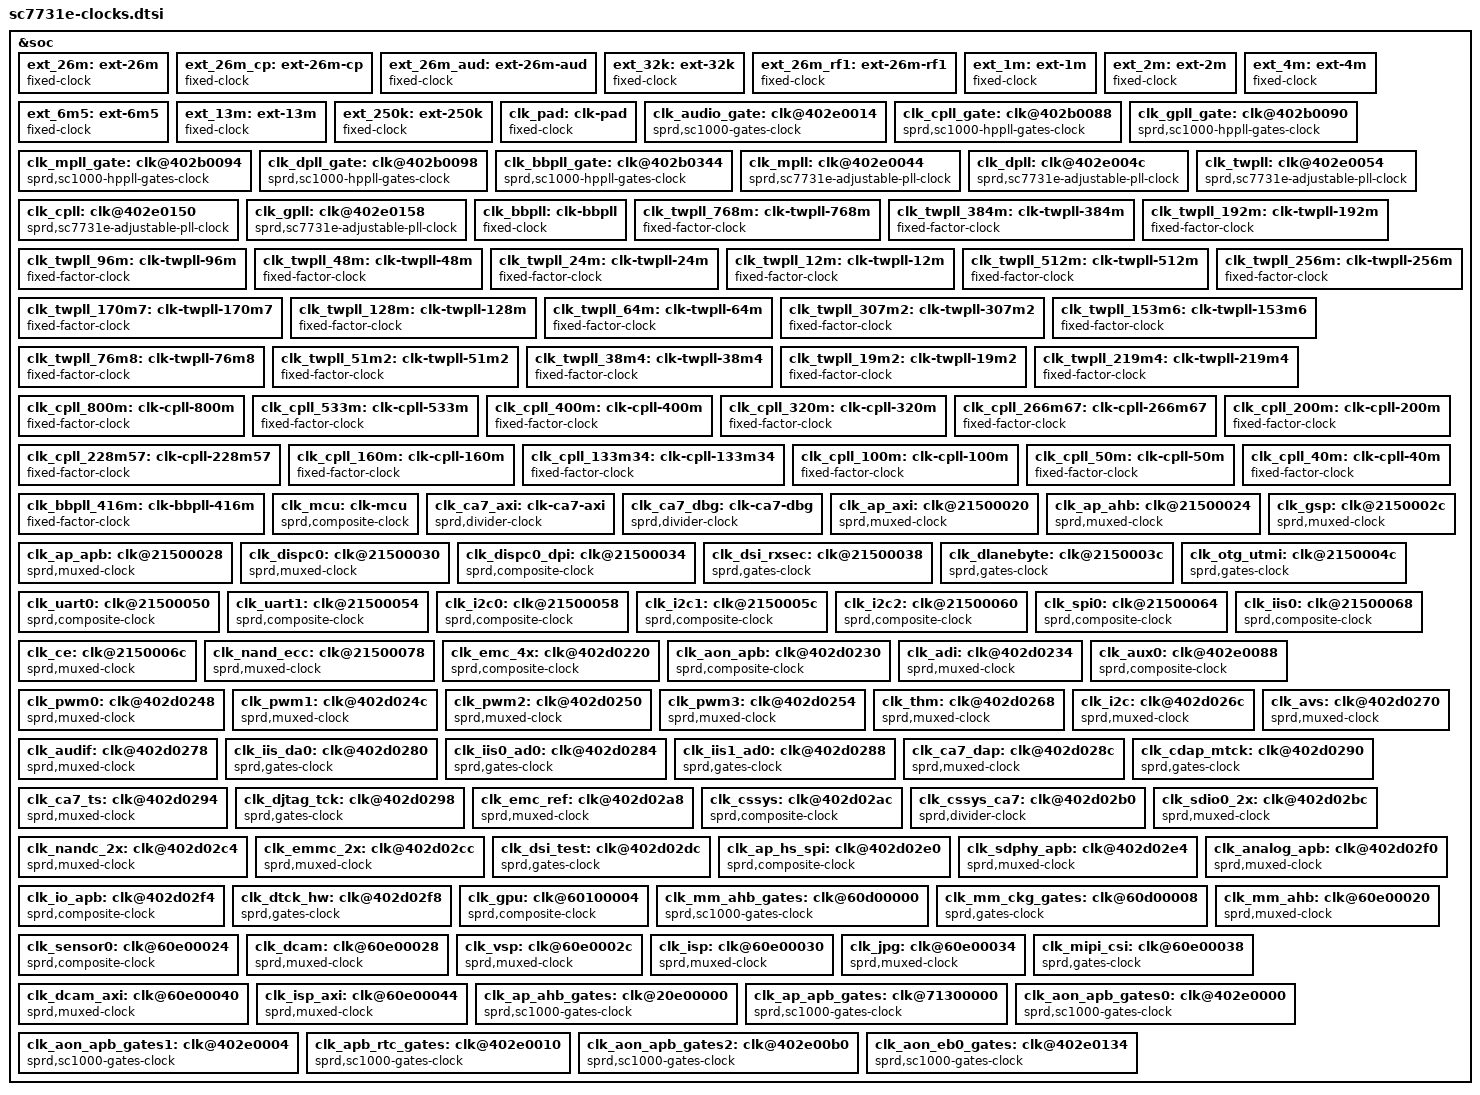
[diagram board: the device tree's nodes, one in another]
/*
 * Spreadtrum Pike2 Series SoC Clock DTS file
 *
 * Copyright (C) 2016, Spreadtrum Communications Inc.
 *
 * This file is licensed under a dual GPLv2 or X11 license.
 */
&soc {
	ext_26m: ext-26m {
		compatible = "fixed-clock";
		#clock-cells = <0>;
		clock-frequency = <26000000>;
		clock-output-names = "ext_26m";
	};

	ext_26m_cp: ext-26m-cp {
		compatible = "fixed-clock";
		#clock-cells = <0>;
		clock-frequency = <26000000>;
		clock-output-names = "ext_26m_cp";
	};

	ext_26m_aud: ext-26m-aud {
		compatible = "fixed-clock";
		#clock-cells = <0>;
		clock-frequency = <26000000>;
		clock-output-names = "ext_26m_aud";
	};

	ext_32k: ext-32k {
		compatible = "fixed-clock";
		#clock-cells = <0>;
		clock-frequency = <32768>;
		clock-output-names = "ext_32k";
	};

	ext_26m_rf1: ext-26m-rf1 {
		compatible = "fixed-clock";
		#clock-cells = <0>;
		clock-frequency = <26000000>;
		clock-output-names = "ext_26m_rf1";
	};

	ext_1m: ext-1m {
		compatible = "fixed-clock";
		#clock-cells = <0>;
		clock-frequency = <1000000>;
		clock-output-names = "ext_1m";
	};

	ext_2m: ext-2m {
		compatible = "fixed-clock";
		#clock-cells = <0>;
		clock-frequency = <2000000>;
		clock-output-names = "ext_2m";
	};

	ext_4m: ext-4m {
		compatible = "fixed-clock";
		#clock-cells = <0>;
		clock-frequency = <4000000>;
		clock-output-names = "ext_4m";
	};

	ext_6m5: ext-6m5 {
		compatible = "fixed-clock";
		#clock-cells = <0>;
		clock-frequency = <6500000>;
		clock-output-names = "ext_6m5";
	};

	ext_13m: ext-13m {
		compatible = "fixed-clock";
		#clock-cells = <0>;
		clock-frequency = <13000000>;
		clock-output-names = "ext_13m";
	};

	ext_250k: ext-250k {
		compatible = "fixed-clock";
		#clock-cells = <0>;
		clock-frequency = <250000>;
		clock-output-names = "ext_250k";
	};

	clk_pad: clk-pad {
		compatible = "fixed-clock";
		#clock-cells = <0>;
		clock-frequency = <64000000>;
		clock-output-names = "clk_pad";
	};

	clk_audio_gate: clk@402e0014 {
		compatible = "sprd,sc1000-gates-clock";
		#clock-cells = <1>;
		sprd,gates-msk = <0x200>;
		reg = <0x402e0014 0x3000>;
		clocks = <&ext_26m>;
		clock-output-names = "clk_audio_gate";
	};

	/* Pll gates */
	clk_cpll_gate: clk@402b0088 {
		compatible = "sprd,sc1000-hppll-gates-clock";
		#clock-cells = <1>;
		sprd,gates-msk = <0x1>;
		reg = <0x402b0088 0x3000>;
		clocks = <&ext_26m>;
		clock-output-names = "clk_cpll_gate";
	};

	clk_gpll_gate: clk@402b0090 {
		compatible = "sprd,sc1000-hppll-gates-clock";
		#clock-cells = <1>;
		sprd,gates-msk = <0x1>;
		reg = <0x402b0090 0x3000>;
		clocks = <&ext_26m>;
		clock-output-names = "clk_gpll_gate";
	};

	clk_mpll_gate: clk@402b0094 {
		compatible = "sprd,sc1000-hppll-gates-clock";
		#clock-cells = <1>;
		sprd,gates-msk = <0x1>;
		reg = <0x402b0094 0x3000>;
		clocks = <&ext_26m>;
		clock-output-names = "clk_mpll_gate";
	};

	clk_dpll_gate: clk@402b0098 {
		compatible = "sprd,sc1000-hppll-gates-clock";
		#clock-cells = <1>;
		sprd,gates-msk = <0x1>;
		reg = <0x402b0098 0x3000>;
		clocks = <&ext_26m>;
		clock-output-names = "clk_dpll_gate";
	};

	clk_bbpll_gate: clk@402b0344 {
		compatible = "sprd,sc1000-hppll-gates-clock";
		#clock-cells = <1>;
		sprd,gates-msk = <0x4>;
		reg = <0x402b0344 0x3000>;
		clocks = <&ext_26m>;
		clock-output-names = "clk_bbpll_gate";
	};

	/* plls */
	clk_mpll: clk@402e0044 {
		compatible = "sprd,sc7731e-adjustable-pll-clock";
		#clock-cells = <0>;
		reg = <0x402e0044 0x4>,
		      <0x402e0048 0x4>;
		clocks = <&clk_mpll_gate 0>;
		clock-output-names = "clk_mpll";
	};

	clk_dpll: clk@402e004c {
		compatible = "sprd,sc7731e-adjustable-pll-clock";
		#clock-cells = <0>;
		reg = <0x402e004c 0x4>,
		      <0x402e0050 0x4>;
		clocks = <&clk_dpll_gate 0>;
		clock-output-names = "clk_dpll";
	};

	clk_twpll: clk@402e0054 {
		compatible = "sprd,sc7731e-adjustable-pll-clock";
		#clock-cells = <0>;
		reg = <0x402e0054 0x4>,
		      <0x402e0058 0x4>;
		clocks = <&ext_26m>;
		clock-output-names = "clk_twpll";
	};

	clk_cpll: clk@402e0150 {
		compatible = "sprd,sc7731e-adjustable-pll-clock";
		#clock-cells = <0>;
		reg = <0x402e0150 0x4>,
		      <0x402e0154 0x4>;
		clocks = <&clk_cpll_gate 0>;
		clock-output-names = "clk_cpll";
	};

	clk_gpll: clk@402e0158 {
		compatible = "sprd,sc7731e-adjustable-pll-clock";
		#clock-cells = <0>;
		reg = <0x402e0158 0x4>,
		      <0x402e015c 0x4>;
		clocks = <&clk_gpll_gate 0>;
		clock-output-names = "clk_gpll";
	};

	clk_bbpll: clk-bbpll {
		compatible = "fixed-clock";
		#clock-cells = <0>;
		clock-frequency = <1248000000>;
		clocks = <&clk_bbpll_gate 2>;
		clock-output-names = "clk_bbpll";
	};

	/* TWPLL divider clocks */
	clk_twpll_768m: clk-twpll-768m {
		compatible = "fixed-factor-clock";
		#clock-cells = <0>;
		clock-mult = <1>;
		clock-div  = <2>;
		clocks = <&clk_twpll>;
		clock-output-names = "clk_twpll_768m";
	};

	clk_twpll_384m: clk-twpll-384m {
		compatible = "fixed-factor-clock";
		#clock-cells = <0>;
		clock-mult = <1>;
		clock-div  = <4>;
		clocks = <&clk_twpll>;
		clock-output-names = "clk_twpll_384m";
	};

	clk_twpll_192m: clk-twpll-192m {
		compatible = "fixed-factor-clock";
		#clock-cells = <0>;
		clock-mult = <1>;
		clock-div  = <8>;
		clocks = <&clk_twpll>;
		clock-output-names = "clk_twpll_192m";
	};

	clk_twpll_96m: clk-twpll-96m {
		compatible = "fixed-factor-clock";
		#clock-cells = <0>;
		clock-mult = <1>;
		clock-div  = <16>;
		clocks = <&clk_twpll>;
		clock-output-names = "clk_twpll_96m";
	};

	clk_twpll_48m: clk-twpll-48m {
		compatible = "fixed-factor-clock";
		#clock-cells = <0>;
		clock-mult = <1>;
		clock-div  = <32>;
		clocks = <&clk_twpll>;
		clock-output-names = "clk_twpll_48m";
	};

	clk_twpll_24m: clk-twpll-24m {
		compatible = "fixed-factor-clock";
		#clock-cells = <0>;
		clock-mult = <1>;
		clock-div  = <64>;
		clocks = <&clk_twpll>;
		clock-output-names = "clk_twpll_24m";
	};

	clk_twpll_12m: clk-twpll-12m {
		compatible = "fixed-factor-clock";
		#clock-cells = <0>;
		clock-mult = <1>;
		clock-div  = <128>;
		clocks = <&clk_twpll>;
		clock-output-names = "clk_twpll_12m";
	};

	clk_twpll_512m: clk-twpll-512m {
		compatible = "fixed-factor-clock";
		#clock-cells = <0>;
		clock-mult = <1>;
		clock-div  = <3>;
		clocks = <&clk_twpll>;
		clock-output-names = "clk_twpll_512m";
	};

	clk_twpll_256m: clk-twpll-256m {
		compatible = "fixed-factor-clock";
		#clock-cells = <0>;
		clock-mult = <1>;
		clock-div  = <6>;
		clocks = <&clk_twpll>;
		clock-output-names = "clk_twpll_256m";
	};

	clk_twpll_170m7: clk-twpll-170m7 {
		compatible = "fixed-factor-clock";
		#clock-cells = <0>;
		clock-mult = <1>;
		clock-div  = <9>;
		clocks = <&clk_twpll>;
		clock-output-names = "clk_twpll_170m7";
	};

	clk_twpll_128m: clk-twpll-128m {
		compatible = "fixed-factor-clock";
		#clock-cells = <0>;
		clock-mult = <1>;
		clock-div  = <12>;
		clocks = <&clk_twpll>;
		clock-output-names = "clk_twpll_128m";
	};

	clk_twpll_64m: clk-twpll-64m {
		compatible = "fixed-factor-clock";
		#clock-cells = <0>;
		clock-mult = <1>;
		clock-div  = <24>;
		clocks = <&clk_twpll>;
		clock-output-names = "clk_twpll_64m";
	};

	clk_twpll_307m2: clk-twpll-307m2 {
		compatible = "fixed-factor-clock";
		#clock-cells = <0>;
		clock-mult = <1>;
		clock-div  = <5>;
		clocks = <&clk_twpll>;
		clock-output-names = "clk_twpll_307m2";
	};

	clk_twpll_153m6: clk-twpll-153m6 {
		compatible = "fixed-factor-clock";
		#clock-cells = <0>;
		clock-mult = <1>;
		clock-div  = <10>;
		clocks = <&clk_twpll>;
		clock-output-names = "clk_twpll_153m6";
	};

	clk_twpll_76m8: clk-twpll-76m8 {
		compatible = "fixed-factor-clock";
		#clock-cells = <0>;
		clock-mult = <1>;
		clock-div  = <20>;
		clocks = <&clk_twpll>;
		clock-output-names = "clk_twpll_76m8";
	};

	clk_twpll_51m2: clk-twpll-51m2 {
		compatible = "fixed-factor-clock";
		#clock-cells = <0>;
		clock-mult = <1>;
		clock-div  = <30>;
		clocks = <&clk_twpll>;
		clock-output-names = "clk_twpll_51m2";
	};

	clk_twpll_38m4: clk-twpll-38m4 {
		compatible = "fixed-factor-clock";
		#clock-cells = <0>;
		clock-mult = <1>;
		clock-div  = <40>;
		clocks = <&clk_twpll>;
		clock-output-names = "clk_twpll_38m4";
	};

	clk_twpll_19m2: clk-twpll-19m2 {
		compatible = "fixed-factor-clock";
		#clock-cells = <0>;
		clock-mult = <1>;
		clock-div  = <80>;
		clocks = <&clk_twpll>;
		clock-output-names = "clk_twpll_19m2";
	};

	clk_twpll_219m4: clk-twpll-219m4 {
		compatible = "fixed-factor-clock";
		#clock-cells = <0>;
		clock-mult = <1>;
		clock-div  = <7>;
		clocks = <&clk_twpll>;
		clock-output-names = "clk_twpll_219m4";
	};

	/* cpll divider clock */
	clk_cpll_800m: clk-cpll-800m {
		compatible = "fixed-factor-clock";
		#clock-cells = <0>;
		clock-mult = <1>;
		clock-div  = <2>;
		clocks = <&clk_cpll>;
		clock-output-names = "clk_cpll_800m";
	};

	clk_cpll_533m: clk-cpll-533m {
		compatible = "fixed-factor-clock";
		#clock-cells = <0>;
		clock-mult = <1>;
		clock-div  = <3>;
		clocks = <&clk_cpll>;
		clock-output-names = "clk_cpll_533m";
	};

	clk_cpll_400m: clk-cpll-400m {
		compatible = "fixed-factor-clock";
		#clock-cells = <0>;
		clock-mult = <1>;
		clock-div  = <4>;
		clocks = <&clk_cpll>;
		clock-output-names = "clk_cpll_400m";
	};

	clk_cpll_320m: clk-cpll-320m {
		compatible = "fixed-factor-clock";
		#clock-cells = <0>;
		clock-mult = <1>;
		clock-div  = <5>;
		clocks = <&clk_cpll>;
		clock-output-names = "clk_cpll_320m";
	};

	clk_cpll_266m67: clk-cpll-266m67 {
		compatible = "fixed-factor-clock";
		#clock-cells = <0>;
		clock-mult = <1>;
		clock-div  = <6>;
		clocks = <&clk_cpll>;
		clock-output-names = "clk_cpll_266m67";
	};

	clk_cpll_228m57: clk-cpll-228m57 {
		compatible = "fixed-factor-clock";
		#clock-cells = <0>;
		clock-mult = <1>;
		clock-div  = <7>;
		clocks = <&clk_cpll>;
		clock-output-names = "clk_cpll_228m57";
	};

	clk_cpll_200m: clk-cpll-200m {
		compatible = "fixed-factor-clock";
		#clock-cells = <0>;
		clock-mult = <1>;
		clock-div  = <8>;
		clocks = <&clk_cpll>;
		clock-output-names = "clk_cpll_200m";
	};

	clk_cpll_160m: clk-cpll-160m {
		compatible = "fixed-factor-clock";
		#clock-cells = <0>;
		clock-mult = <1>;
		clock-div  = <10>;
		clocks = <&clk_cpll>;
		clock-output-names = "clk_cpll_160m";
	};

	clk_cpll_133m34: clk-cpll-133m34 {
		compatible = "fixed-factor-clock";
		#clock-cells = <0>;
		clock-mult = <1>;
		clock-div  = <12>;
		clocks = <&clk_cpll>;
		clock-output-names = "clk_cpll_133m34";
	};

	clk_cpll_100m: clk-cpll-100m {
		compatible = "fixed-factor-clock";
		#clock-cells = <0>;
		clock-mult = <1>;
		clock-div  = <16>;
		clocks = <&clk_cpll>;
		clock-output-names = "clk_cpll_100m";
	};

	clk_cpll_50m: clk-cpll-50m {
		compatible = "fixed-factor-clock";
		#clock-cells = <0>;
		clock-mult = <1>;
		clock-div  = <32>;
		clocks = <&clk_cpll>;
		clock-output-names = "clk_cpll_50m";
	};

	clk_cpll_40m: clk-cpll-40m {
		compatible = "fixed-factor-clock";
		#clock-cells = <0>;
		clock-mult = <1>;
		clock-div  = <40>;
		clocks = <&clk_cpll>;
		clock-output-names = "clk_cpll_40m";
	};

	clk_bbpll_416m: clk-bbpll-416m {
		compatible = "fixed-factor-clock";
		#clock-cells = <0>;
		clock-mult = <1>;
		clock-div  = <3>;
		clocks = <&clk_bbpll>;
		clock-output-names = "clk_bbpll_416m";
	};

	/* ap clocks */
	clk_mcu: clk-mcu {
		compatible = "sprd,composite-clock";
		#clock-cells = <0>;
		reg = <0x20e00054 0x4>,
		      <0x20e00038 0x4>;
		sprd,mux-msk = <0x7>;
		sprd,div-msk = <0x70>;
		clocks = <&ext_26m>, <&clk_twpll_512m>,
			 <&clk_twpll_768m>, <&clk_dpll>,
			 <&clk_cpll>, <&clk_twpll>, <&clk_mpll>;
		clock-output-names = "clk_mcu";
	};

	clk_ca7_axi: clk-ca7-axi {
		compatible = "sprd,divider-clock";
		#clock-cells = <0>;
		sprd,div-msk = <0x700>;
		clocks = <&clk_mcu>;
		clock-output-names = "clk_ca7_axi";
	};

	clk_ca7_dbg: clk-ca7-dbg {
		compatible = "sprd,divider-clock";
		#clock-cells = <0>;
		sprd,div-msk = <0x70000>;
		clocks = <&clk_mcu>;
		clock-output-names = "clk_ca7_dbg";
	};

	clk_ap_axi: clk@21500020 {
		compatible = "sprd,muxed-clock";
		#clock-cells = <0>;
		reg = <0x21500020 0x4>;
		sprd,mux-msk = <0x7>;
		clocks = <&ext_26m>, <&clk_twpll_76m8>,
			 <&clk_twpll_128m>, <&clk_twpll_256m>,
			 <&clk_cpll_266m67>;
		clock-output-names = "clk_ap_axi";
	};

	clk_ap_ahb: clk@21500024 {
		compatible = "sprd,muxed-clock";
		#clock-cells = <0>;
		reg = <0x21500024 0x4>;
		sprd,mux-msk = <0x7>;
		clocks = <&ext_26m>, <&clk_twpll_76m8>,
			 <&clk_twpll_128m>, <&clk_twpll_192m>,
			 <&clk_cpll_200m>;
		clock-output-names = "clk_ap_ahb";
	};

	clk_ap_apb: clk@21500028 {
		compatible = "sprd,muxed-clock";
		#clock-cells = <0>;
		reg = <0x21500028 0x4>;
		sprd,mux-msk = <0x7>;
		clocks = <&ext_26m>, <&clk_twpll_64m>,
			 <&clk_twpll_96m>, <&clk_cpll_100m>,
			 <&clk_twpll_128m>;
		clock-output-names = "clk_ap_apb";
	};

	clk_gsp: clk@2150002c {
		compatible = "sprd,muxed-clock";
		#clock-cells = <0>;
		reg = <0x2150002c 0x4>;
		sprd,mux-msk = <0x7>;
		clocks = <&clk_twpll_153m6>, <&clk_twpll_256m>,
			 <&clk_twpll_307m2>, <&clk_cpll_320m>,
			 <&clk_twpll_384m>;
		clock-output-names = "clk_gsp";
	};

	clk_dispc0: clk@21500030 {
		compatible = "sprd,muxed-clock";
		#clock-cells = <0>;
		reg = <0x21500030 0x4>;
		sprd,mux-msk = <0x7>;
		clocks = <&clk_twpll_128m>, <&clk_twpll_153m6>,
			 <&clk_twpll_192m>, <&clk_twpll_256m>,
			 <&clk_cpll_320m>, <&clk_twpll_384m>;
		clock-output-names = "clk_dispc0";
	};

	clk_dispc0_dpi:clk@21500034 {
		compatible = "sprd,composite-clock";
		#clock-cells = <0>;
		reg = <0x21500034 0x4>;
		sprd,mux-msk = <0x7>;
		sprd,div-msk = <0xf00>;
		clocks = <&clk_twpll_96m>, <&clk_cpll_100m>,
			 <&clk_twpll_128m>, <&clk_twpll_153m6>,
			 <&clk_twpll_192m>;
		clock-output-names = "clk_dispc0_dpi";
	};

	clk_dsi_rxsec: clk@21500038 {
		compatible = "sprd,gates-clock";
		#clock-cells = <1>;
		reg = <0x21500038 0x4>;
		sprd,gates-msk = <0x10000>;
		clocks = <&clk_ap_ahb>;
		clock-output-names = "clk_dsi_rxsec";
	};

	clk_dlanebyte: clk@2150003c {
		compatible = "sprd,gates-clock";
		#clock-cells = <1>;
		reg = <0x2150003c 0x4>;
		sprd,gates-msk = <0x10000>;
		clocks = <&clk_ap_ahb>;
		clock-output-names = "clk_dlanebyte";
	};

	clk_otg_utmi: clk@2150004c {
		compatible = "sprd,gates-clock";
		#clock-cells = <1>;
		reg = <0x2150004c 0x4>;
		sprd,gates-msk = <0x10000>;
		clocks = <&clk_ap_ahb>;
		clock-output-names = "clk_otg_utmi";
	};

	clk_uart0:clk@21500050 {
		compatible = "sprd,composite-clock";
		#clock-cells = <0>;
		reg = <0x21500050 0x4>;
		sprd,mux-msk = <0x3>;
		sprd,div-msk = <0x700>;
		clocks = <&ext_26m>, <&clk_twpll_48m>,
			 <&clk_twpll_51m2>, <&clk_twpll_96m>;
		clock-output-names = "clk_uart0";
	};

	clk_uart1:clk@21500054 {
		compatible = "sprd,composite-clock";
		#clock-cells = <0>;
		reg = <0x21500054 0x4>;
		sprd,mux-msk = <0x3>;
		sprd,div-msk = <0x700>;
		clocks = <&ext_26m>, <&clk_twpll_48m>,
			 <&clk_twpll_51m2>, <&clk_twpll_96m>;
		clock-output-names = "clk_uart1";
	};

	clk_i2c0:clk@21500058 {
		compatible = "sprd,composite-clock";
		#clock-cells = <0>;
		reg = <0x21500058 0x4>;
		sprd,mux-msk = <0x3>;
		sprd,div-msk = <0x700>;
		clocks = <&ext_26m>, <&clk_twpll_48m>,
			 <&clk_twpll_51m2>, <&clk_twpll_153m6>;
		clock-output-names = "clk_i2c0";
	};

	clk_i2c1:clk@2150005c {
		compatible = "sprd,composite-clock";
		#clock-cells = <0>;
		reg = <0x2150005c 0x4>;
		sprd,mux-msk = <0x3>;
		sprd,div-msk = <0x700>;
		clocks = <&ext_26m>, <&clk_twpll_48m>,
			 <&clk_twpll_51m2>, <&clk_twpll_153m6>;
		clock-output-names = "clk_i2c1";
	};

	clk_i2c2:clk@21500060 {
		compatible = "sprd,composite-clock";
		#clock-cells = <0>;
		reg = <0x21500060 0x4>;
		sprd,mux-msk = <0x3>;
		sprd,div-msk = <0x700>;
		clocks = <&ext_26m>, <&clk_twpll_48m>,
			 <&clk_twpll_51m2>, <&clk_twpll_153m6>;
		clock-output-names = "clk_i2c2";
	};

	clk_spi0:clk@21500064 {
		compatible = "sprd,composite-clock";
		#clock-cells = <0>;
		reg = <0x21500064 0x4>;
		sprd,mux-msk = <0x7>;
		sprd,div-msk = <0x700>;
		clocks = <&ext_26m>, <&clk_cpll_100m>,
			 <&clk_twpll_128m>, <&clk_twpll_153m6>,
			 <&clk_twpll_192m>;
		clock-output-names = "clk_spi0";
	};

	clk_iis0:clk@21500068 {
		compatible = "sprd,composite-clock";
		#clock-cells = <0>;
		reg = <0x21500068 0x4>;
		sprd,mux-msk = <0x3>;
		sprd,div-msk = <0x700>;
		clocks = <&ext_26m>, <&clk_twpll_128m>, <&clk_twpll_153m6>;
		clock-output-names = "clk_iis0";
	};

	clk_ce: clk@2150006c {
		compatible = "sprd,muxed-clock";
		#clock-cells = <0>;
		reg = <0x2150006c 0x4>;
		sprd,mux-msk = <0x7>;
		clocks = <&ext_26m>, <&clk_twpll_96m>,
			 <&clk_cpll_100m>, <&clk_twpll_192m>,
			 <&clk_twpll_256m>;
		clock-output-names = "clk_ce";
	};

	clk_nand_ecc: clk@21500078 {
		compatible = "sprd,muxed-clock";
		#clock-cells = <0>;
		reg = <0x21500078 0x4>;
		sprd,mux-msk = <0x3>;
		clocks = <&ext_26m>, <&clk_cpll_200m>,
			 <&clk_twpll_256m>, <&clk_twpll_307m2>;
		clock-output-names = "clk_nand_ecc";
	};

	/* aon clocks */
	clk_emc_4x:clk@402d0220 {
		compatible = "sprd,composite-clock";
		#clock-cells = <0>;
		reg = <0x402d0220 0x4>;
		sprd,mux-msk = <0x7>;
		sprd,div-msk = <0x300>;
		clocks = <&ext_26m>, <&clk_twpll_384m>,
			 <&clk_twpll_512m>, <&clk_twpll_768m>,
			 <&clk_cpll_800m>, <&clk_dpll>;
		clock-output-names = "clk_emc_4x";
	};

	clk_aon_apb:clk@402d0230 {
		compatible = "sprd,composite-clock";
		#clock-cells = <0>;
		reg = <0x402d0230 0x4>;
		sprd,mux-msk = <0x3>;
		sprd,div-msk = <0x300>;
		clocks = <&ext_26m>, <&clk_cpll_100m>,
			 <&clk_twpll_128m>;
		clock-output-names = "clk_aon_apb";
	};

	clk_adi: clk@402d0234 {
		compatible = "sprd,muxed-clock";
		#clock-cells = <0>;
		reg = <0x402d0234 0x4>;
		sprd,mux-msk = <0x3>;
		clocks = <&ext_26m>, <&clk_cpll_50m>,
			 <&clk_twpll_51m2>;
		clock-output-names = "clk_adi";
	};

	clk_aux0: clk@402e0088 {
		compatible = "sprd,composite-clock";
		#clock-cells = <0>;
		reg = <0x402e0088 0x4>;
		sprd,mux-msk = <0x3>;
		sprd,div-msk = <0xf0000>;
		clocks = <&ext_32k>, <&ext_26m_cp>,
			 <&ext_26m>;
		clock-output-names = "clk_aux0";
	};

	clk_pwm0: clk@402d0248 {
		compatible = "sprd,muxed-clock";
		#clock-cells = <0>;
		reg = <0x402d0248 0x4>;
		sprd,mux-msk = <0x7>;
		clocks = <&ext_32k>, <&ext_26m_cp>,
			 <&ext_26m>, <&clk_cpll_40m>,
			 <&clk_twpll_48m>;
		clock-output-names = "clk_pwm0";
	};

	clk_pwm1: clk@402d024c {
		compatible = "sprd,muxed-clock";
		#clock-cells = <0>;
		reg = <0x402d024c 0x4>;
		sprd,mux-msk = <0x7>;
		clocks = <&ext_32k>, <&ext_26m_cp>,
			 <&ext_26m>, <&clk_cpll_40m>,
			 <&clk_twpll_48m>;
		clock-output-names = "clk_pwm1";
	};

	clk_pwm2: clk@402d0250 {
		compatible = "sprd,muxed-clock";
		#clock-cells = <0>;
		reg = <0x402d0250 0x4>;
		sprd,mux-msk = <0x7>;
		clocks = <&ext_32k>, <&ext_26m_cp>,
			 <&ext_26m>, <&clk_cpll_40m>,
			 <&clk_twpll_48m>;
		clock-output-names = "clk_pwm2";
	};

	clk_pwm3: clk@402d0254 {
		compatible = "sprd,muxed-clock";
		#clock-cells = <0>;
		reg = <0x402d0254 0x4>;
		sprd,mux-msk = <0x7>;
		clocks = <&ext_32k>, <&ext_26m_cp>,
			 <&ext_26m>, <&clk_cpll_40m>,
			 <&clk_twpll_48m>;
		clock-output-names = "clk_pwm3";
	};

	clk_thm: clk@402d0268 {
		compatible = "sprd,muxed-clock";
		#clock-cells = <0>;
		reg = <0x402d0268 0x4>;
		sprd,mux-msk = <0x1>;
		clocks = <&ext_32k>, <&ext_250k>;
		clock-output-names = "clk_thm";
	};

	clk_i2c: clk@402d026c {
		compatible = "sprd,muxed-clock";
		#clock-cells = <0>;
		reg = <0x402d026c 0x4>;
		sprd,mux-msk = <0x7>;
		clocks = <&ext_26m>, <&clk_twpll_48m>,
			 <&clk_twpll_51m2>, <&clk_cpll_133m34>,
			 <&clk_twpll_153m6>;
		clock-output-names = "clk_i2c";
	};

	clk_avs: clk@402d0270 {
		compatible = "sprd,muxed-clock";
		#clock-cells = <0>;
		reg = <0x402d0270 0x4>;
		sprd,mux-msk = <0x7>;
		clocks = <&ext_26m>, <&clk_twpll_48m>,
			 <&clk_cpll_50m>, <&clk_twpll_51m2>,
			 <&clk_twpll_96m>;
		clock-output-names = "clk_avs";
	};

	clk_audif: clk@402d0278 {
		compatible = "sprd,muxed-clock";
		#clock-cells = <0>;
		reg = <0x402d0278 0x4>;
		sprd,mux-msk = <0x3>;
		clocks = <&ext_26m_aud>, <&clk_twpll_38m4>,
			 <&clk_cpll_50m>, <&clk_twpll_51m2>;
		clock-output-names = "clk_audif";
	};

	clk_iis_da0: clk@402d0280 {
		compatible = "sprd,gates-clock";
		#clock-cells = <1>;
		reg = <0x402d0280 0x4>;
		sprd,gates-msk = <0x10000>;
		clocks = <&clk_aon_apb>;
		clock-output-names = "clk_iis_da0";
	};

	clk_iis0_ad0: clk@402d0284 {
		compatible = "sprd,gates-clock";
		#clock-cells = <1>;
		reg = <0x402d0284 0x4>;
		sprd,gates-msk = <0x10000>;
		clocks = <&clk_aon_apb>;
		clock-output-names = "clk_iis0_ad0";
	};

	clk_iis1_ad0: clk@402d0288 {
		compatible = "sprd,gates-clock";
		#clock-cells = <1>;
		reg = <0x402d0288 0x4>;
		sprd,gates-msk = <0x10000>;
		clocks = <&clk_aon_apb>;
		clock-output-names = "clk_iis1_ad0";
	};

	clk_ca7_dap: clk@402d028c {
		compatible = "sprd,muxed-clock";
		#clock-cells = <0>;
		reg = <0x402d028c 0x4>;
		sprd,mux-msk = <0x3>;
		clocks = <&ext_26m_aud>, <&clk_twpll_76m8>,
			 <&clk_cpll_100m>, <&clk_twpll_153m6>;
		clock-output-names = "clk_ca7_dap";
	};

	clk_cdap_mtck: clk@402d0290 {
		compatible = "sprd,gates-clock";
		#clock-cells = <1>;
		reg = <0x402d0290 0x4>;
		sprd,gates-msk = <0x10000>;
		clocks = <&clk_aon_apb>;
		clock-output-names = "clk_cdap_mtck";
	};

	clk_ca7_ts: clk@402d0294 {
		compatible = "sprd,muxed-clock";
		#clock-cells = <0>;
		reg = <0x402d0294 0x4>;
		sprd,mux-msk = <0x7>;
		clocks = <&ext_32k>, <&ext_26m>,
			 <&clk_twpll_128m>, <&clk_cpll_133m34>,
			 <&clk_twpll_153m6>;
		clock-output-names = "clk_ca7_ts";
	};

	clk_djtag_tck: clk@402d0298 {
		compatible = "sprd,gates-clock";
		#clock-cells = <1>;
		reg = <0x402d0298 0x4>;
		sprd,gates-msk = <0x10000>;
		clocks = <&clk_aon_apb>;
		clock-output-names = "clk_djtag_tck";
	};

	clk_emc_ref: clk@402d02a8 {
		compatible = "sprd,muxed-clock";
		#clock-cells = <0>;
		reg = <0x402d02a8 0x4>;
		sprd,mux-msk = <0x3>;
		clocks = <&ext_6m5>, <&ext_13m>, <&ext_26m>;
		clock-output-names = "clk_emc_ref";
	};

	clk_cssys:clk@402d02ac {
		compatible = "sprd,composite-clock";
		#clock-cells = <0>;
		reg = <0x402d02ac 0x4>;
		sprd,mux-msk = <0x7>;
		sprd,div-msk = <0x300>;
		clocks = <&ext_26m>, <&clk_twpll_96m>,
			 <&clk_twpll_128m>, <&clk_twpll_153m6>,
			 <&clk_cpll_266m67>, <&clk_twpll_384m>,
			 <&clk_twpll_512m>;
		clock-output-names = "clk_cssys";
	};

	clk_cssys_ca7: clk@402d02b0 {
		compatible = "sprd,divider-clock";
		#clock-cells = <0>;
		reg = <0x402d02b0 0x4>;
		sprd,div-msk = <0x100>;
		clocks = <&clk_cssys>;
		clock-output-names = "clk_cssys_ca7";
	};

	clk_sdio0_2x: clk@402d02bc {
		compatible = "sprd,muxed-clock";
		#clock-cells = <0>;
		reg = <0x402d02bc 0x4>;
		sprd,mux-msk = <0x7>;
		clocks = <&ext_1m>, <&ext_26m>, <&clk_twpll_307m2>,
			 <&clk_twpll_384m>, <&clk_cpll_400m>,
			 <&clk_bbpll_416m>;
		clock-output-names = "clk_sdio0_2x";
	};

	clk_nandc_2x: clk@402d02c4 {
		compatible = "sprd,muxed-clock";
		#clock-cells = <0>;
		reg = <0x402d02c4 0x4>;
		sprd,mux-msk = <0x7>;
		clocks = <&ext_1m>, <&ext_26m>, <&clk_twpll_153m6>,
			 <&clk_twpll_170m7>, <&clk_cpll_200m>,
			 <&clk_twpll_219m4>, <&clk_cpll_228m57>,
			 <&clk_cpll_266m67>;
		clock-output-names = "clk_nandc_2x";
	};

	clk_emmc_2x: clk@402d02cc {
		compatible = "sprd,muxed-clock";
		#clock-cells = <0>;
		reg = <0x402d02cc 0x4>;
		sprd,mux-msk = <0x7>;
		clocks = <&ext_1m>, <&ext_26m>, <&clk_twpll_307m2>,
			 <&clk_twpll_384m>, <&clk_cpll_400m>,
			 <&clk_bbpll_416m>;
		clock-output-names = "clk_emmc_2x";
	};

	clk_dsi_test: clk@402d02dc {
		compatible = "sprd,gates-clock";
		#clock-cells = <1>;
		reg = <0x402d02dc 0x4>;
		sprd,gates-msk = <0x10000>;
		clocks = <&clk_aon_apb>;
		clock-output-names = "clk_dsi_test";
	};

	clk_ap_hs_spi:clk@402d02e0 {
		compatible = "sprd,composite-clock";
		#clock-cells = <0>;
		reg = <0x402d02e0 0x4>;
		sprd,mux-msk = <0x7>;
		sprd,div-msk = <0x700>;
		clocks = <&ext_26m>, <&clk_twpll_128m>,
			 <&clk_cpll_133m34>, <&clk_twpll_153m6>,
			 <&clk_twpll_192m>;
		clock-output-names = "clk_ap_hs_spi";
	};

	clk_sdphy_apb: clk@402d02e4 {
		compatible = "sprd,muxed-clock";
		#clock-cells = <0>;
		reg = <0x402d02e4 0x4>;
		sprd,mux-msk = <0x3>;
		clocks = <&ext_26m>, <&clk_cpll_40m>,
			 <&clk_twpll_48m>;
		clock-output-names = "clk_sdphy_apb";
	};

	clk_analog_apb: clk@402d02f0 {
		compatible = "sprd,muxed-clock";
		#clock-cells = <0>;
		reg = <0x402d02f0 0x4>;
		sprd,mux-msk = <0x7>;
		clocks = <&ext_26m>, <&clk_cpll_40m>,
			 <&clk_twpll_48m>;
		clock-output-names = "clk_analog_apb";
	};

	clk_io_apb: clk@402d02f4 {
		compatible = "sprd,composite-clock";
		#clock-cells = <0>;
		reg = <0x402d02f4 0x4>;
		sprd,mux-msk = <0x3>;
		sprd,div-msk = <0x300>;
		clocks = <&ext_26m>, <&clk_cpll_40m>,
			 <&clk_twpll_48m>;
		clock-output-names = "clk_io_apb";
	};

	clk_dtck_hw: clk@402d02f8 {
		compatible = "sprd,gates-clock";
		#clock-cells = <1>;
		reg = <0x402d02f8 0x4>;
		sprd,gates-msk = <0x10000>;
		clocks = <&clk_aon_apb>;
		clock-output-names = "clk_dtck_hw";
	};

	/* gpu clocks */
	clk_gpu:clk@60100004 {
		compatible = "sprd,composite-clock";
		#clock-cells = <0>;
		reg = <0x60100004 0x4>;
		sprd,mux-msk = <0x7>;
		sprd,div-msk = <0x30>;
		clocks = <&clk_twpll_153m6>, <&clk_twpll_192m>,
			 <&clk_twpll_256m>, <&clk_twpll_307m2>,
			 <&clk_twpll_384m>, <&clk_twpll_512m>,
			 <&clk_gpll>;
		clock-output-names = "clk_gpu";
	};

	/* mm domain clocks */
	clk_mm_ahb_gates: clk@60d00000 {
		compatible = "sprd,sc1000-gates-clock";
		#clock-cells = <1>;
		reg = <0x60d00000 0x3000>;
		sprd,gates-msk = <0x7f>;
		clocks = <&clk_mm_ahb>;
		clock-output-names = "dcam_eb", "isp_eb", "vsp_eb",
				     "csi_eb", "jpg_eb", "mm_ckg_eb",
				     "vsp_mq_ahb_eb";
	};

	clk_mm_ckg_gates: clk@60d00008 {
		compatible = "sprd,gates-clock";
		#clock-cells = <1>;
		reg = <0x60d00008 0x4>;
		sprd,gates-msk = <0x1f>;
		clocks = <&clk_mm_ahb>;
		clock-output-names = "mcphy_cfg_eb", "msensor0_en",
				     "misp_axi_en", "mdcam_axi_en",
				     "mmipi_csi_en";
	};

	clk_mm_ahb: clk@60e00020 {
		compatible = "sprd,muxed-clock";
		#clock-cells = <0>;
		reg = <0x60e00020 0x4>;
		sprd,mux-msk = <0x7>;
		clocks = <&ext_26m>, <&clk_twpll_96m>,
			 <&clk_twpll_128m>, <&clk_twpll_153m6>,
			 <&clk_cpll_160m>;
		clock-output-names = "clk_mm_ahb";
	};

	clk_sensor0:clk@60e00024 {
		compatible = "sprd,composite-clock";
		#clock-cells = <0>;
		reg = <0x60e00024 0x4>;
		sprd,mux-msk = <0x3>;
		sprd,div-msk = <0x700>;
		clocks = <&ext_26m>, <&clk_twpll_48m>,
			 <&clk_twpll_76m8>, <&clk_twpll_96m>;
		clock-output-names = "clk_sensor0";
	};

	clk_dcam: clk@60e00028 {
		compatible = "sprd,muxed-clock";
		#clock-cells = <0>;
		reg = <0x60e00028 0x4>;
		sprd,mux-msk = <0x3>;
		clocks = <&clk_twpll_128m>, <&clk_twpll_256m>,
			 <&clk_twpll_307m2>, <&clk_cpll_320m>;
		clock-output-names = "clk_dcam";
	};

	clk_vsp: clk@60e0002c {
		compatible = "sprd,muxed-clock";
		#clock-cells = <0>;
		reg = <0x60e0002c 0x4>;
		sprd,mux-msk = <0x3>;
		clocks = <&clk_twpll_128m>, <&clk_twpll_256m>,
			 <&clk_twpll_307m2>, <&clk_cpll_320m>;
		clock-output-names = "clk_vsp";
	};

	clk_isp: clk@60e00030 {
		compatible = "sprd,muxed-clock";
		#clock-cells = <0>;
		reg = <0x60e00030 0x4>;
		sprd,mux-msk = <0x3>;
		clocks = <&clk_twpll_128m>, <&clk_twpll_256m>,
			 <&clk_twpll_307m2>, <&clk_cpll_320m>;
		clock-output-names = "clk_isp";
	};

	clk_jpg: clk@60e00034 {
		compatible = "sprd,muxed-clock";
		#clock-cells = <0>;
		reg = <0x60e00034 0x4>;
		sprd,mux-msk = <0x3>;
		clocks = <&clk_twpll_76m8>, <&clk_twpll_128m>,
			 <&clk_twpll_256m>, <&clk_cpll_266m67>;
		clock-output-names = "clk_jpg";
	};

	clk_mipi_csi: clk@60e00038 {
		compatible = "sprd,gates-clock";
		#clock-cells = <1>;
		reg = <0x60e00038 0x4>;
		sprd,gates-msk = <0x10000>;
		clocks = <&clk_mm_ahb>;
		clock-output-names = "clk_mipi_csi";
	};

	clk_dcam_axi: clk@60e00040 {
		compatible = "sprd,muxed-clock";
		#clock-cells = <0>;
		reg = <0x60e00040 0x4>;
		sprd,mux-msk = <0x3>;
		clocks = <&clk_twpll_307m2>, <&clk_cpll_320m>,
			 <&clk_twpll_512m>, <&clk_cpll_533m>;
		clock-output-names = "clk_dcam_axi";
	};

	clk_isp_axi: clk@60e00044 {
		compatible = "sprd,muxed-clock";
		#clock-cells = <0>;
		reg = <0x60e00044 0x4>;
		sprd,mux-msk = <0x3>;
		clocks = <&clk_twpll_307m2>, <&clk_cpll_320m>,
			 <&clk_twpll_512m>, <&clk_cpll_533m>;
		clock-output-names = "clk_isp_axi";
	};

	/* ap ahb gates */
	clk_ap_ahb_gates: clk@20e00000 {
		compatible = "sprd,sc1000-gates-clock";
		#clock-cells = <1>;
		sprd,gates-msk = <0x58001d7b>;
		reg = <0x20e00000 0x3000>;
		clocks = <&clk_ap_axi>;
		clock-output-names = "dsi_eb", "dispc_eb", "gsp_eb",
				     "otg_eb", "ree_dma_eb", "ce_pub_eb",
				     "sdio0_eb", "nandc_eb", "emmc_eb",
				     "ce_sec_eb", "emmc_32k_eb",
				     "sdio0_32k_eb", "nandc_ecc_eb";
	};

	/* ap apb gates */
	clk_ap_apb_gates: clk@71300000 {
		compatible = "sprd,sc1000-gates-clock";
		#clock-cells = <1>;
		sprd,gates-msk = <0x7a6723>;
		reg = <0x71300000 0x3000>;
		clocks = <&clk_ap_apb>;
		clock-output-names = "sim0_eb", "iis0_eb", "spi0_eb",
				     "i2c0_eb", "i2c1_eb", "i2c2_eb",
				     "uart0_eb", "uart1_eb", "sim0_32k_eb",
				     "intc0_eb", "intc1_eb", "intc2_eb",
				     "intc3_eb";
	};

	/* Aon Apb Gates */
	clk_aon_apb_gates0: clk@402e0000 {
		compatible = "sprd,sc1000-gates-clock";
		#clock-cells = <1>;
		sprd,gates-msk = <0xff5ffff8>;
		reg = <0x402e0000 0x3000>;
		clocks = <&clk_aon_apb>;
		clock-output-names = "gpio_eb", "pwm0_eb", "pwm1_eb",
				     "pwm2_eb", "pwm3_eb", "kpd_eb",
				     "aon_syst_eb", "ap_syst_eb",
				     "aon_tmr_eb", "ap_tmr0_eb",
				     "ree_efuse_eb", "eic_eb", "intc_eb",
				     "adi_eb", "audif_eb", "aud_eb",
				     "vbc_eb", "pin_eb", "splk_eb",
				     "ap_wdg_eb", "mm_eb", "aon_ckg_eb",
				     "gpu_eb", "ca7_ts0_eb", "ca7_ts1_eb",
				     "ca7_dap_eb", "i2c_eb";
	};

	clk_aon_apb_gates1: clk@402e0004 {
		compatible = "sprd,sc1000-gates-clock";
		#clock-cells = <1>;
		sprd,gates-msk = <0xf3f66fff>;
		reg = <0x402e0004 0x3000>;
		clocks = <&clk_aon_apb>;
		clock-output-names = "pmu_eb", "thm_eb", "aux0_eb",
				     "aux1_eb", "aux2_eb", "probe_eb",
				     "avs_eb", "clk_emc_ref_eb",
				     "ca7_wdg_eb", "ap_tmr1_eb",
				     "ap_tmr2_eb", "djtag_apb_eb",
				     "gsp_emc_eb", "mm_vsp_eb",
				     "mdar_eb", "rtc4m0_cal_eb",
				     "djtag_eb", "mbox_eb",
				     "ree_aon_dma_eb", "cm4_djtag_eb",
				     "wcn_eb", "def_eb", "dbg_eb",
				     "dbg_emc_eb", "cross_trig_eb",
				     "serdes_dphy_eb";
	};

	clk_apb_rtc_gates: clk@402e0010 {
		compatible = "sprd,sc1000-gates-clock";
		#clock-cells = <1>;
		sprd,gates-msk = <0x7ffff>;
		reg = <0x402e0010 0x3000>;
		clocks = <&clk_aon_apb>;
		clock-output-names = "arch_rtc_eb", "kpd_rtc_eb",
				     "aon_syst_rtc_eb", "ap_syst_rtc_eb",
				     "aon_tmr_rtc_eb", "ap_tmr0_rtc_eb",
				     "eic_rtc_eb", "eic_rtcdiv5_eb",
				     "ap_wdg_rtc_eb", "ca7_wdg_rtc_eb",
				     "thm_rtc_eb", "arm_ta_rtc_eb",
				     "gpu_ta_rtc_eb", "arm_ta_rtc_aen",
				     "gpu_ta_rtc_aen", "ap_tmr1_rtc_eb",
				     "ap_tmr2_rtc_eb", "dcxo_lc_rtc_eb",
				     "bb_cal_rtc_eb";
	};

	clk_aon_apb_gates2: clk@402e00b0 {
		compatible = "sprd,sc1000-gates-clock";
		#clock-cells = <1>;
		sprd,gates-msk = <0xfff0>;
		reg = <0x402e00b0 0x3000>;
		clocks = <&clk_aon_apb>;
		clock-output-names = "cssys_eb", "dmc_eb", "pub_reg_eb",
				     "rosc_eb", "sdphy_cfg_eb",
				     "sdphy_ref_eb", "busmon_dma_eb",
				     "anlg_eb", "pin_apb_eb",
				     "anlg_apb_eb", "bsmtmr_eb",
				     "ap_dap_eb";
	};

	clk_aon_eb0_gates: clk@402e0134 {
		compatible = "sprd,sc1000-gates-clock";
		#clock-cells = <1>;
		sprd,gates-msk = <0x40fff>;
		reg = <0x402e0134 0x3000>;
		clocks = <&clk_aon_apb>;
		clock-output-names = "emmc_1x_eb", "emmc_2x_eb",
				     "sdio0_1x_eb", "sdio0_2x_eb",
				     "sdio1_1x_eb", "sdio1_2x_eb",
				     "nandc_1x_eb", "nandc_2x_eb",
				     "cssys_ca7_eb", "ap_hs_spi_eb",
				     "det_32k_eb", "tmr_eb",
				     "apll_test_eb";
	};
};
